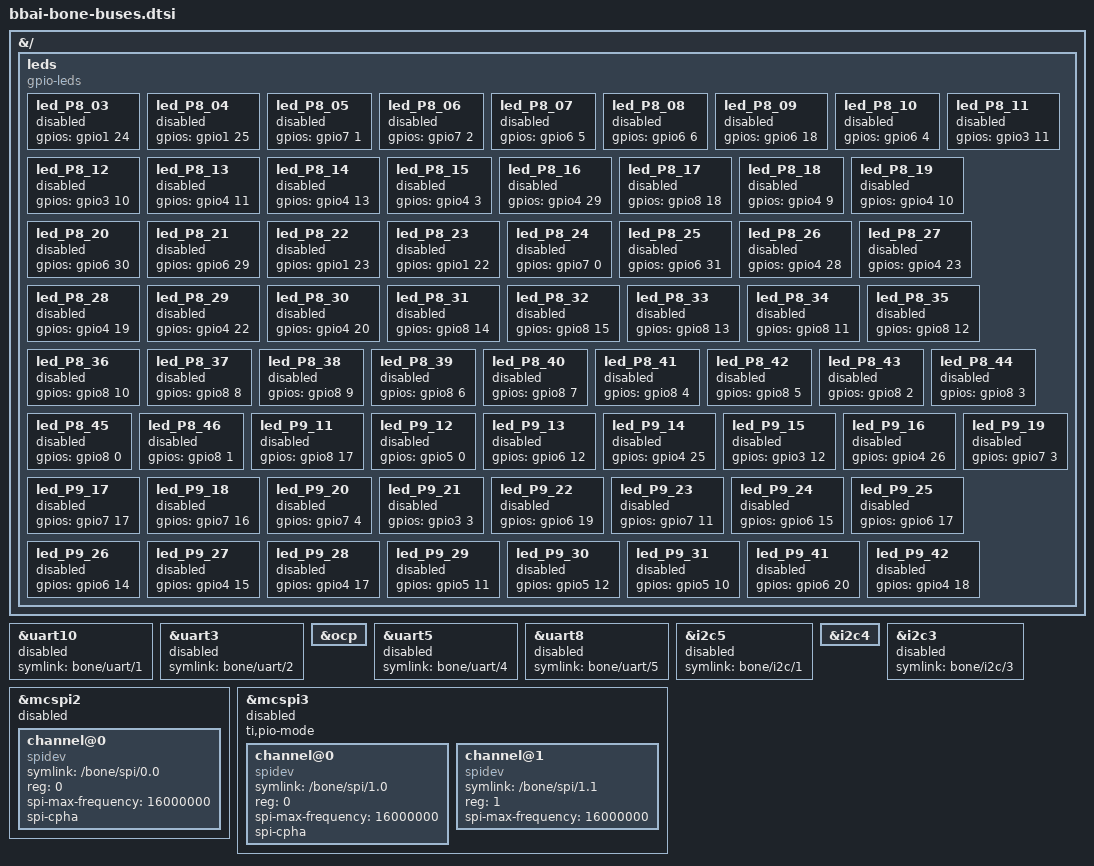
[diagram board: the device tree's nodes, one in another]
/*
 * Copyright (C) 2020 Deepak Khatri <deepaklorkhatri7@gmail.com>
 *
 * This program is free software; you can redistribute it and/or modify
 * it under the terms of the GNU General Public License version 2 as
 * published by the Free Software Foundation.
 */

#include <dt-bindings/board/am572x-bbai-pins.h>

/********/
/* LEDs */
/********/
&{/} {
	leds {
		pinctrl-names = "default";
		compatible = "gpio-leds";

		led_P8_03 {
			gpios = <&gpio1 24 0>;
			status = "reserved";
		};

		led_P8_04 {
			gpios = <&gpio1 25 0>;
			status = "reserved";
		};

		led_P8_05 {
			gpios = <&gpio7 1 0>;
			status = "reserved";
		};

		led_P8_06 {
			gpios = <&gpio7 2 0>;
			status = "reserved";
		};

		led_P8_07 {
			gpios = <&gpio6 5 0>;
			status = "reserved";
		};

		led_P8_08 {
			gpios = <&gpio6 6 0>;
			status = "reserved";
		};

		led_P8_09 {
			gpios = <&gpio6 18 0>;
			status = "reserved";
		};

		led_P8_10 {
			gpios = <&gpio6 4 0>;
			status = "reserved";
		};

		led_P8_11 {
			gpios = <&gpio3 11 0>;
			status = "reserved";
		};

		led_P8_12 {
			gpios = <&gpio3 10 0>;
			status = "reserved";
		};

		led_P8_13 {
			gpios = <&gpio4 11 0>;
			status = "reserved";
		};

		led_P8_14 {
			gpios = <&gpio4 13 0>;
			status = "reserved";
		};

		led_P8_15 {
			gpios = <&gpio4 3 0>;
			status = "reserved";
		};

		led_P8_16 {
			gpios = <&gpio4 29 0>;
			status = "reserved";
		};

		led_P8_17 {
			gpios = <&gpio8 18 0>;
			status = "reserved";
		};

		led_P8_18 {
			gpios = <&gpio4 9 0>;
			status = "reserved";
		};

		led_P8_19 {
			gpios = <&gpio4 10 0>;
			status = "reserved";
		};

		led_P8_20 {
			gpios = <&gpio6 30 0>;
			status = "reserved";
		};

		led_P8_21 {
			gpios = <&gpio6 29 0>;
			status = "reserved";
		};

		led_P8_22 {
			gpios = <&gpio1 23 0>;
			status = "reserved";
		};

		led_P8_23 {
			gpios = <&gpio1 22 0>;
			status = "reserved";
		};

		led_P8_24 {
			gpios = <&gpio7 0 0>;
			status = "reserved";
		};

		led_P8_25 {
			gpios = <&gpio6 31 0>;
			status = "reserved";
		};

		led_P8_26 {
			gpios = <&gpio4 28 0>;
			status = "reserved";
		};

		led_P8_27 {
			gpios = <&gpio4 23 0>;
			status = "reserved";
		};

		led_P8_28 {
			gpios = <&gpio4 19 0>;
			status = "reserved";
		};

		led_P8_29 {
			gpios = <&gpio4 22 0>;
			status = "reserved";
		};

		led_P8_30 {
			gpios = <&gpio4 20 0>;
			status = "reserved";
		};

		led_P8_31 {
			gpios = <&gpio8 14 0>;
			status = "reserved";
		};

		led_P8_32 {
			gpios = <&gpio8 15 0>;
			status = "reserved";
		};

		led_P8_33 {
			gpios = <&gpio8 13 0>;
			status = "reserved";
		};

		led_P8_34 {
			gpios = <&gpio8 11 0>;
			status = "reserved";
		};

		led_P8_35 {
			gpios = <&gpio8 12 0>;
			status = "reserved";
		};

		led_P8_36 {
			gpios = <&gpio8 10 0>;
			status = "reserved";
		};

		led_P8_37 {
			gpios = <&gpio8 8 0>;
			status = "reserved";
		};

		led_P8_38 {
			gpios = <&gpio8 9 0>;
			status = "reserved";
		};

		led_P8_39 {
			gpios = <&gpio8 6 0>;
			status = "reserved";
		};

		led_P8_40 {
			gpios = <&gpio8 7 0>;
			status = "reserved";
		};

		led_P8_41 {
			gpios = <&gpio8 4 0>;
			status = "reserved";
		};

		led_P8_42 {
			gpios = <&gpio8 5 0>;
			status = "reserved";
		};

		led_P8_43 {
			gpios = <&gpio8 2 0>;
			status = "reserved";
		};

		led_P8_44 {
			gpios = <&gpio8 3 0>;
			status = "reserved";
		};

		led_P8_45 {
			gpios = <&gpio8 0 0>;
			status = "reserved";
		};

		led_P8_46 {
			gpios = <&gpio8 1 0>;
			status = "reserved";
		};

		led_P9_11 {
			gpios = <&gpio8 17 0>;
			status = "reserved";
		};

		led_P9_12 {
			gpios = <&gpio5 0 0>;
			status = "reserved";
		};

		led_P9_13 {
			gpios = <&gpio6 12 0>;
			status = "reserved";
		};

		led_P9_14 {
			gpios = <&gpio4 25 0>;
			status = "reserved";
		};

		led_P9_15 {
			gpios = <&gpio3 12 0>;
			status = "reserved";
		};

		led_P9_16 {
			gpios = <&gpio4 26 0>;
			status = "reserved";
		};

		led_P9_17 {
			gpios = <&gpio7 17 0>;
			status = "reserved";
		};

		led_P9_18 {
			gpios = <&gpio7 16 0>;
			status = "reserved";
		};

		led_P9_19 {
			gpios = <&gpio7 3 0>;
			status = "reserved";
		};

		led_P9_20 {
			gpios = <&gpio7 4 0>;
			status = "reserved";
		};

		led_P9_21 {
			gpios = <&gpio3 3 0>;
			status = "reserved";
		};

		led_P9_22 {
			gpios = <&gpio6 19 0>;
			status = "reserved";
		};

		led_P9_23 {
			gpios = <&gpio7 11 0>;
			status = "reserved";
		};

		led_P9_24 {
			gpios = <&gpio6 15 0>;
			status = "reserved";
		};

		led_P9_25 {
			gpios = <&gpio6 17 0>;
			status = "reserved";
		};

		led_P9_26 {
			gpios = <&gpio6 14 0>;
			status = "reserved";
		};

		led_P9_27 {
			gpios = <&gpio4 15 0>;
			status = "reserved";
		};

		led_P9_28 {
			gpios = <&gpio4 17 0>;
			status = "reserved";
		};

		led_P9_29 {
			gpios = <&gpio5 11 0>;
			status = "reserved";
		};

		led_P9_30 {
			gpios = <&gpio5 12 0>;
			status = "reserved";
		};

		led_P9_31 {
			gpios = <&gpio5 10 0>;
			status = "reserved";
		};

		led_P9_41 {
			gpios = <&gpio6 20 0>;
			status = "reserved";
		};

		led_P9_42 {
			gpios = <&gpio4 18 0>;
			status = "reserved";
		};
	};
};


// UARTs
bone_uart_1: &uart10 {
	status = "disabled";
	pinctrl-names = "default";
	symlink = "bone/uart/1";
};

bone_uart_2: &uart3 {
	status = "disabled";
	pinctrl-names = "default";
	symlink = "bone/uart/2";
};

bone_uart_3: &ocp{
	// not available
};

bone_uart_4: &uart5 {
	status = "disabled";
	pinctrl-names = "default";
	symlink = "bone/uart/4";
};

bone_uart_5: &uart8 {
	status = "disabled";
	pinctrl-names = "default";
	symlink = "bone/uart/5";
};

// I2Cs
bone_i2c_1: &i2c5 {
	status = "disabled";
	pinctrl-names = "default";
	symlink = "bone/i2c/1";
};

bone_i2c_2: &i2c4 {
	// status = "disabled";
	pinctrl-names = "default";
	// symlink = "bone/i2c/2";
};

bone_i2c_2a: &ocp {
	// Not available
};

bone_i2c_3: &i2c3 {
	status = "disabled";
	pinctrl-names = "default";
	symlink = "bone/i2c/3";
};

// SPIs
bone_spi_0: &mcspi2 {
	#address-cells = <1>;
	#size-cells = <0>;

	status = "disabled";
	pinctrl-names = "default";

	channel@0 {
		#address-cells = <1>;
		#size-cells = <0>;

		compatible = "spidev";
		symlink = "/bone/spi/0.0";

		reg = <0>;
		spi-max-frequency = <16000000>;
		spi-cpha;
	};
};

bone_spi_1: &mcspi3 {
	#address-cells = <1>;
	#size-cells = <0>;

	status = "disabled";
	pinctrl-names = "default";
	ti,pio-mode; /* disable dma when used as an overlay, dma gets stuck at 160 bits... */

	channel@0 {
		#address-cells = <1>;
		#size-cells = <0>;

		compatible = "spidev";
		symlink = "/bone/spi/1.0";

		reg = <0>;
		spi-max-frequency = <16000000>;
		spi-cpha;
	};

	channel@1 {
		#address-cells = <1>;
		#size-cells = <0>;

		compatible = "spidev";
		symlink = "/bone/spi/1.1";

		reg = <1>;
		spi-max-frequency = <16000000>;
	};
};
